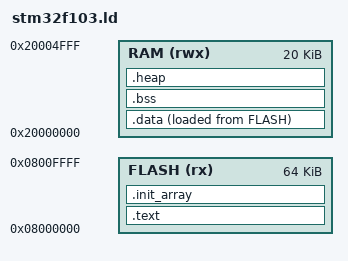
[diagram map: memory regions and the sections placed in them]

MEMORY
{
    FLASH (rx) : ORIGIN = 0x08000000, LENGTH = 64K
    RAM (rwx)  : ORIGIN = 0x20000000, LENGTH = 20K
}

SECTIONS
{
    .text :
    {
        KEEP(*(.isr_vector))
        *(.text*)
        *(.rodata*)
        . = ALIGN(4);
        _etext = .;
    } > FLASH

    /* Секция для инициализации C++ и стандартной библиотеки */
    .init_array :
    {
        . = ALIGN(4);
        __init_array_start = .;
        KEEP (*(SORT(.init_array.*)))
        KEEP (*(.init_array*))
        __init_array_end = .;
    } > FLASH

    .data : 
    {
        . = ALIGN(4);
        _sdata = .;
        *(.data*)
        . = ALIGN(4);
        _edata = .;
    } > RAM AT > FLASH

    .bss :
    {
        . = ALIGN(4);
        _sbss = .;
        __bss_start__ = _sbss;
        *(.bss*)
        *(COMMON)
        . = ALIGN(4);
        _ebss = .;
        __bss_end__ = _ebss;
    } > RAM

    .heap :
    {
        . = ALIGN(4);
        end = .;
        _end = .;
        *(.heap*)
        . = . + 0x400; /* 1KB heap */
    } > RAM
}
